# MCXN947_cm33_core0 register map
Vendor: nxp.com; File version: 1.0
CPU: CM33 r2p0, little endian, MPU, FPU, VTOR, 3 interrupt priority bits
Registers are 32-bit, read-write, reset 0x0 unless marked. A register's access mark holds for its fields unless they carry their own. Offsets are from the block's base; [hi:lo] are bit positions; lines under a group give offsets from that group; {n}, {i} and the like mark numbered series; 'fields as' and 'values as' point back to an identical list.

## USBFS0 — USBFS
Base 0x400DD000
0x00 PERID 8-bit ro reset 0x4 — Peripheral ID
  [5:0] ID — Peripheral Identification
0x04 IDCOMP 8-bit ro reset 0xFB — Peripheral ID Complement
  [5:0] NID — Negative Peripheral ID
0x08 REV 8-bit ro reset 0x33 — Peripheral Revision
  [7:0] REV — Revision
0x0C ADDINFO 8-bit ro reset 0x1 — Peripheral Additional Information
  [0] IEHOST — Host Mode Enable
    0=DISABLED; 1=ENABLED
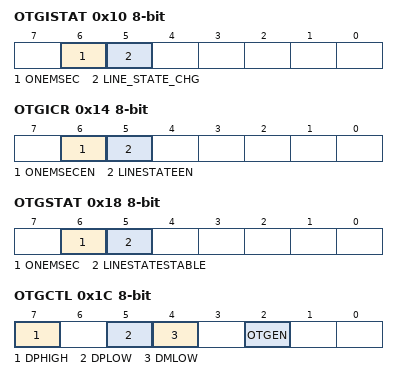
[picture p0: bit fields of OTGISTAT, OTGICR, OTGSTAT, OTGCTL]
0x10 OTGISTAT 8-bit write-1-clears — OTG Interrupt Status
  [6] ONEMSEC write-1-clears — One Millisecond Timer Timeout Flag
    on read: 0=INT_NO (Not timed out); 1=INT_YES (Timed out)
  [5] LINE_STATE_CHG write-1-clears — Line State Change Interrupt Flag
    on read: 0=INT_NO (Interrupt did not occur); 1=INT_YES (Interrupt occurred)
0x14 OTGICR 8-bit — OTG Interrupt Control
  [6] ONEMSECEN — 1-Millisecond Interrupt Enable
    0=DIS_TIMER_INT (Disable); 1=EN_TIMER_INT (Enable)
  [5] LINESTATEEN — Line State Change Interrupt Enable
    0=DIS_LINEST_INT (Disable); 1=EN_LINEST_INT (Enable)
0x18 OTGSTAT 8-bit ro — OTG Status
  [6] ONEMSEC — Reserved for 1 ms count
  [5] LINESTATESTABLE
    0=LINEST_NOT_STABLE (Unstable); 1=LINEST_STABLE (Stable)
0x1C OTGCTL 8-bit — OTG Control
  [7] DPHIGH — D+ Data Line Pullup Resistor Enable
    0=DIS_DP_PULLUP (Disable); 1=EN_DP_PULLUP (Enable)
  [5] DPLOW — D+ Data Line pulldown Resistor Enable
    0=DIS_DP_PULLDOWN (Disable); 1=EN_DP_PULLDOWN (Enable)
  [4] DMLOW — D- Data Line Pulldown Resistor Enable
    0=DIS_DM_PULLDOWN (Disable); 1=EN_DM_PULLDOWN (Enable)
  [2] OTGEN — On-The-Go Pullup and Pulldown Resistor Enable
    0=CONFIG_RESISTORS_CTL (If USBENSOFEN is 1 and HOSTMODEEN is 0 in the Control Register (CTL), then the D+ Data line pullup resistors are enabled. If HOSTMODEEN is 1, then the D+ and D- Data line pulldown resistors are engaged.); 1=CONFIG_RESISTORS_HERE (Uses the pullup and pulldown controls in this register.)
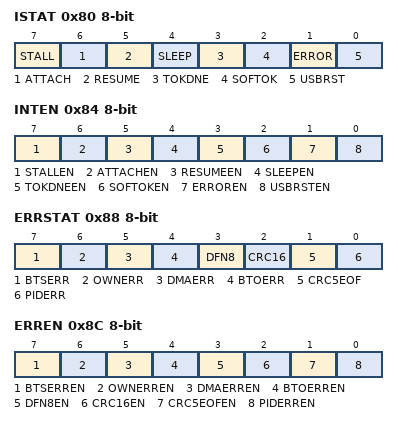
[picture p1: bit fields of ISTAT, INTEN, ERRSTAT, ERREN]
0x80 ISTAT 8-bit write-1-clears — Interrupt Status
  [7] STALL write-1-clears — Stall Interrupt Flag
    values as OTGISTAT.LINE_STATE_CHG
  [6] ATTACH write-1-clears — Attach Interrupt Flag
    on read: 0=INT_NO (Not detected); 1=INT_YES (Detected)
  [5] RESUME write-1-clears — Resume Flag
    values as OTGISTAT.LINE_STATE_CHG
  [4] SLEEP write-1-clears — Sleep Flag
    values as OTGISTAT.LINE_STATE_CHG
  [3] TOKDNE write-1-clears — Current Token Processing Flag
    on read: 0=INT_NO (Not processed); 1=INT_YES (Processed)
  [2] SOFTOK write-1-clears — Start Of Frame (SOF) Token Flag
    on read: 0=INT_NO (Did not receive); 1=INT_YES (Received)
  [1] ERROR write-1-clears — Error Flag
    on read: 0=INT_NO (Error did not occur); 1=INT_YES (Error occurred)
  [0] USBRST write-1-clears — USB Reset Flag
    on read: 0=INT_NO (Not detected); 1=INT_YES (Detected)
0x84 INTEN 8-bit — Interrupt Enable
  [7] STALLEN — STALL Interrupt Enable
    0=DIS_STALL_INT (Disable); 1=EN_STALL_INT (Enable)
  [6] ATTACHEN — ATTACH Interrupt Enable
    0=DIS_ATTACH_INT (Disable); 1=EN_ATTACH_INT (Enable)
  [5] RESUMEEN — RESUME Interrupt Enable
    0=DIS_RESUME_INT (Disable); 1=EN_RESUME_INT (Enable)
  [4] SLEEPEN — SLEEP Interrupt Enable
    0=DIS_SLEEP_INT (Disable); 1=EN_SLEEP_INT (Enable)
  [3] TOKDNEEN — TOKDNE Interrupt Enable
    0=DIS_TOKDNE_INT (Disable); 1=EN_TOKDNE_INT (Enable)
  [2] SOFTOKEN — SOFTOK Interrupt Enable
    0=DIS_SOFTOK_INT (Disable); 1=EN_SOFTOK_INT (Enable)
  [1] ERROREN — ERROR Interrupt Enable
    0=DIS_ERROR_INT (Disable); 1=EN_ERROR_INT (Enable)
  [0] USBRSTEN — USBRST Interrupt Enable
    0=DIS_USBRST_INT (Disable); 1=EN_USBRST_INT (Enable)
0x88 ERRSTAT 8-bit write-1-clears — Error Interrupt Status
  [7] BTSERR write-1-clears — Bit Stuff Error Flag
    on read: 0=INT_NO (Packet not rejected due to the error); 1=INT_YES (Packet rejected due to the error)
  [6] OWNERR write-1-clears — BD Unavailable Error Flag
    values as OTGISTAT.LINE_STATE_CHG
  [5] DMAERR write-1-clears — DMA Access Error Flag
    values as OTGISTAT.LINE_STATE_CHG
  [4] BTOERR write-1-clears — Bus Turnaround Timeout Error Flag
    on read: 0=INT_NO (Not timed out); 1=INT_YES (Timed out)
  [3] DFN8 write-1-clears — Data Field Not 8 Bits Flag
    on read: 0=INT_NO (Integer number of bytes); 1=INT_YES (Not an integer number of bytes)
  [2] CRC16 write-1-clears — CRC16 Error Flag
    on read: 0=INT_NO (Not rejected); 1=INT_YES (Rejected)
  [1] CRC5EOF write-1-clears — CRC5 Error or End of Frame Error Flag
    values as OTGISTAT.LINE_STATE_CHG
  [0] PIDERR write-1-clears — PID Error Flag
    on read: 0=INT_NO (Did not fail); 1=INT_YES (Failed)
0x8C ERREN 8-bit — Error Interrupt Enable
  [7] BTSERREN — BTSERR (Bit Stuff Error) Interrupt Enable
    0=DIS_BTSERREN_INT (Disable); 1=EN_BTSERREN_INT (Enable)
  [6] OWNERREN — OWNERR Interrupt Enable
    0=DIS_OWNERR_INT (Disable); 1=EN_OWNERR_INT (Enable)
  [5] DMAERREN — DMAERR Interrupt Enable
    0=DIS_DMAERR_INT (Disable); 1=EN_DMAERR_INT (Enable)
  [4] BTOERREN — BTOERR (Bus Timeout Error) Interrupt Enable
    0=DIS_BTOERR_INT (Disable); 1=EN_BTOERR_INT (Enable)
  [3] DFN8EN — DFN8 (Data Field Not Integer Number of Bytes) Interrupt Enable
    0=DIS_DFN8_INT (Disable); 1=EN_DFN8_INT (Enable)
  [2] CRC16EN — CRC16 Interrupt Enable
    0=DIS_CRC16_INT (Disable); 1=EN_CRC16_INT (Enable)
  [1] CRC5EOFEN — CRC5/EOF Interrupt Enable
    0=DIS_CRC5_INT (Disable); 1=EN_CRC5_INT (Enable)
  [0] PIDERREN — PIDERR Interrupt Enable
    0=DIS_PIDERR_INT (Disable); 1=EN_PIDERR_INT (Enable)
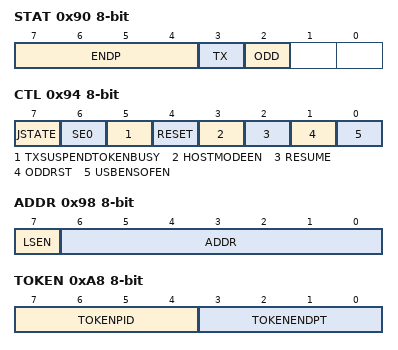
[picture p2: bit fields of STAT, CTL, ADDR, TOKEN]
0x90 STAT 8-bit ro — Status
  [7:4] ENDP — Endpoint address
  [3] TX — Transmit Indicator
    0=RX_TRANSACTION (Receive); 1=TX_TRANSACTION (Transmit)
  [2] ODD — Odd Bank
    0=NOT_IN_ODD_BANK (Not in the odd bank); 1=ODD_BANK (In the odd bank)
0x94 CTL 8-bit — Control
  [7] JSTATE — Live USB Differential Receiver JSTATE Signal
  [6] SE0 — Live USB Single-Ended Zero signal
  [5] TXSUSPENDTOKENBUSY — TXD Suspend And Token Busy
  [4] RESET — Reset Signaling Enable
    0=DISABLE; 1=ENABLE
  [3] HOSTMODEEN — Host Mode Enable
    0=EN_DEVICE_MODE (USBFS operates in Device mode.); 1=EN_HOST_MODE (USBFS operates in Host mode. In Host mode, USBFS performs USB transactions under the programmed control of the host processor.)
  [2] RESUME
  [1] ODDRST — Odd Reset
  [0] USBENSOFEN — USB Enable
    0=DIS_USB_SOF (Disable); 1=EN_USB_SOF (Enable)
0x98 ADDR 8-bit — Address
  [7] LSEN — Low Speed Enable
  [6:0] ADDR — USB Address
0x9C BDTPAGE1 8-bit
  [7:1] BDTBA — BDT Base Address
0xA0 FRMNUML 8-bit ro — Frame Number Register Low
  [7:0] FRM — Frame Number, Bits 0-7
0xA4 FRMNUMH 8-bit ro — Frame Number Register High
  [2:0] FRM — Frame Number, Bits 8-10
0xA8 TOKEN 8-bit
  [7:4] TOKENPID — Token Type
    1=EN_OUT_TOKEN (OUT token. USBFS performs an OUT (TX) transaction.); 9=EN_IN_TOKEN (IN token. USBFS performs an IN (RX) transaction.); 13=EN_SETUP_TOKEN (SETUP token. USBFS performs a SETUP (TX) transaction)
  [3:0] TOKENENDPT — Token Endpoint Address
0xAC SOFTHLD 8-bit — SOF Threshold
  [7:0] CNT — SOF Count Threshold
0xB0 BDTPAGE2 8-bit
  [7:0] BDTBA — BDT Base Address
0xB4 BDTPAGE3 8-bit
  [7:0] BDTBA — BDT Base Address
{0xC0+4i} ENDPOINT[{i}] (i=0..15) group
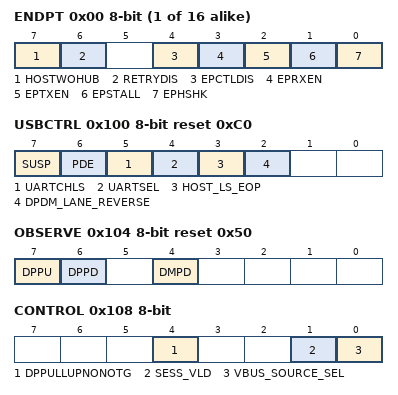
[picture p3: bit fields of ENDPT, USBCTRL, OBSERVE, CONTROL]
  0x00 ENDPT 8-bit — Endpoint Control
    [7] HOSTWOHUB — Host Without A Hub
      0=LS_THRU_HUB (Connected using a hub (USBFS generates PRE_PID as required)); 1=LS_DIRECT_CONNECT (Connected directly to host without a hub, or was used to attach)
    [6] RETRYDIS — Retry Disable
      0=RETRIED (Retried NAK'ed transactions in hardware.); 1=DO_NOT_RETRIED (Do not retry NAK'ed transactions. When a transaction is NAK'ed, the BDT PID field is updated with the NAK PID, and the TOKEN_DNE interrupt becomes 1.)
    [4] EPCTLDIS — Control Transfer Disable
      0=Enable; 1=Disable
    [3] EPRXEN — Endpoint for RX transfers enable
    [2] EPTXEN — Endpoint for TX transfers enable
    [1] EPSTALL — Endpoint Stalled
    [0] EPHSHK — Endpoint Handshaking Enable
0x100 USBCTRL 8-bit reset 0xC0 — USB Control
  [7] SUSP — Suspend
    0=XCVR_NOT_SUSPEND (Not in Suspend state); 1=XCVR_SUSPEND (In Suspend state)
  [6] PDE — Pulldown Enable
    0=DIS_PULLDOWNS (Disable on D+ and D-); 1=EN_PULLDOWNS (Enable on D+ and D-)
  [5] UARTCHLS — UART Signal Channel Select
    0=UART_DP_TX (USB DP and DM signals are used as UART TX/RX.); 1=UART_DM_TX (USB DP and DM signals are used as UART RX/TX.)
  [4] UARTSEL — UART Select
    0=USB_MODE (USB DP and DM external package pins are used for USB signaling.); 1=UART_MODE (USB DP and DM external package pins are used for UART signaling.)
  [3] HOST_LS_EOP — Host-Mode-Only Low-Speed Device EOP Signaling
    0=HOST_FS_RESUME_EOP (Full-speed device or a low-speed device through a hub); 1=HOST_LS_RESUME_EOP (Directly-connected low-speed device)
  [2] DPDM_LANE_REVERSE — DP and DM Lane Reversal Control
    0=DP_DM_STANDARD (Standard USB DP and DM package pin assignment); 1=DP_DM_REVERSED (Reverse roles of USB DP and DM package pins)
0x104 OBSERVE 8-bit ro reset 0x50 — USB OTG Observe
  [7] DPPU — D+ Pullup
    0=DP_PU_DIS_STAT (Disabled); 1=DP_PU_EN_STAT (Enabled)
  [6] DPPD — D+ Pulldown
    0=DP_PD_DIS_STAT (Disabled); 1=DP_PD_EN_STAT (Enabled)
  [4] DMPD — D- Pulldown
    0=DM_PD_DIS_STAT (Disabled); 1=DM_PD_EN_STAT (Enabled)
0x108 CONTROL 8-bit — USB OTG Control
  [4] DPPULLUPNONOTG — DP Pullup in Non-OTG Device Mode
    0=DIS_DEVICE_DP_PU (Disable); 1=EN_DEVICE_DP_PU (Enabled)
  [1] SESS_VLD ro — VBUS Session Valid status
    0=SESS_VLD_LOW (Below); 1=SESS_VLD_HIGH (Above)
  [0] VBUS_SOURCE_SEL — VBUS Monitoring Source Select
    1=RESISTIVE (Resistive divider attached to a GPIO pin)
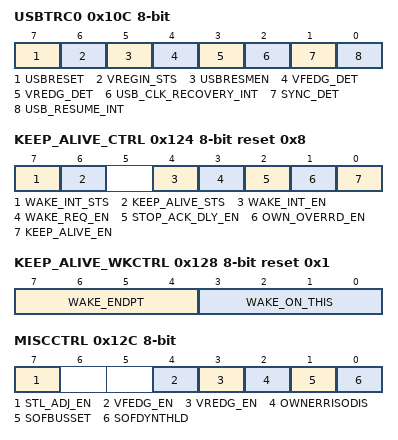
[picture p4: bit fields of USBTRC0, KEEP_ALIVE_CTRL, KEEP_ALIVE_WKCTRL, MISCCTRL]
0x10C USBTRC0 8-bit — USB Transceiver Control 0
  [7] USBRESET wo
    0=NORMAL_OPERATION (Normal USBFS operation); 1=FORCE_HARD_RESET (Returns USBFS to its reset state)
  [6] VREGIN_STS ro — VREGIN Status
  [5] USBRESMEN — Asynchronous Resume Interrupt Enable
    0=DIS_ASYNC_WAKEUP (Disable); 1=EN_ASYNC_WAKEUP (Enable)
  [4] VFEDG_DET ro — VREGIN Falling Edge Interrupt Detect
    0=NO_VREG_FE_INT (Not detected); 1=VREG_FE_INT_DETECTED (Detected)
  [3] VREDG_DET ro — VREGIN Rising Edge Interrupt Detect
    0=NO_VREG_RE_INT (Not detected); 1=VREG_RE_INT_DETECTED (Detected)
  [2] USB_CLK_RECOVERY_INT ro — Combined USB Clock Recovery interrupt status
  [1] SYNC_DET ro — Synchronous USB Interrupt Detect
    0=NO_SYNC_INT (Not detected); 1=SYNC_INT_DETECTED (Detected)
  [0] USB_RESUME_INT ro — USB Asynchronous Interrupt
    0=NO_ASYNC_INT (Not generated); 1=SYNC_INT_GENERATED (Generated because of the USB asynchronous interrupt)
0x114 USBFRMADJUST 8-bit — Frame Adjust
  [7:0] ADJ — Frame Adjustment
0x124 KEEP_ALIVE_CTRL 8-bit reset 0x8 — Keep Alive Mode Control
  [7] WAKE_INT_STS write-1-clears — Wakeup Interrupt Status Flag
    values as OTGISTAT.LINE_STATE_CHG
  [6] KEEP_ALIVE_STS ro — Keep Alive Status
    0=KEEP_ALIVE_DIS_STAT (Not in Keep Alive mode); 1=KEEP_ALIVE_EN_STAT (In Keep Alive mode)
  [4] WAKE_INT_EN — Wakeup Interrupt Enable
  [3] WAKE_REQ_EN — Wakeup Request Enable
    0=DIS_WAKE_REQUEST (Disable); 1=EN_WAKE_REQUEST (Enable)
  [2] STOP_ACK_DLY_EN — Stop Acknowledge Delay Enable
    0=ENTER_KEEP_ALIVE_ON_IDLE (Enter KEEP_ALIVE mode immediately when there is no USB AHB transfer.); 1=ENTER_KEEP_ALIVE_IMMEDIATE (Enter KEEP_ALIVE mode until the USB core is idle and there is no USB AHB transfer.)
  [1] OWN_OVERRD_EN — OWN Bit Override Enable
  [0] KEEP_ALIVE_EN — Keep Alive Mode Enable
    0=DE_ASSERTED (Everything remains same as before.); 1=ASSERTED (USB shall enter USB_KEEP_ALIVE mode after asserting ipg_stop.)
0x128 KEEP_ALIVE_WKCTRL 8-bit reset 0x1 — Keep Alive Mode Wakeup Control
  [7:4] WAKE_ENDPT ro — Endpoint address for the wakeup request
  [3:0] WAKE_ON_THIS — Token PID for the wakeup request
    1=WAKE_ON_OUT_SETUP (Wake up after receiving OUT or SETUP token packet.); 13=WAKE_ON_SETUP_ONLY (Wake up after receiving SETUP token packet. All other values are reserved.)
0x12C MISCCTRL 8-bit — Miscellaneous Control
  [7] STL_ADJ_EN — USB Peripheral Mode Stall Adjust Enable
    0=STALL_BOTH_IN_OUT (If ENDPTn[END_STALL] = 1, both IN and OUT directions for the associated endpoint stalls.); 1=STALL_SINGLE_DIRECTION (If ENDPTn[END_STALL] = 1, the STALL_xx_DIS registers control which directions for the associated endpoint stalls.)
  [4] VFEDG_EN — VREGIN Falling Edge Interrupt Enable
    0=DIS_VREGIN_FE_INT (Disable); 1=EN_VREGIN_FE_INT (Enable)
  [3] VREDG_EN — VREGIN Rising Edge Interrupt Enable
    0=DIS_VREGIN_RE_INT (Disable); 1=EN_VREGIN_RE_INT (Enable)
  [2] OWNERRISODIS — OWN Error Detect for ISO IN and ISO OUT Disable
    0=DIS_OWN_ERROR_DETECT_ISO (Enable); 1=EN_OWN_ERROR_DETECT_ISO (Disable)
  [1] SOFBUSSET — SOF_TOK Interrupt Generation Mode Select
    0=SOF_TOK_INT_FROM_THRESHOLD (According to the SOF threshold value); 1=SOF_TOK_INT_COUNTER_0 (When the SOF counter reaches 0)
  [0] SOFDYNTHLD — Dynamic SOF Threshold Compare mode
    0=USE_DYN_SOF_THRESHOLD (When the byte-times SOF threshold is reached); 1=USE_FIXED_SOF_THRESHOLD (When 8 byte-times SOF threshold is reached or overstepped)
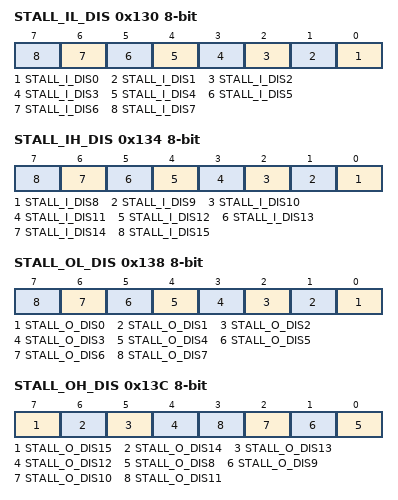
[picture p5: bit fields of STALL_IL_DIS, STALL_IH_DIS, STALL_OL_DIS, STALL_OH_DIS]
0x130 STALL_IL_DIS 8-bit — Peripheral Mode Stall Disable for Endpoints 7 to 0 in IN Direction
  [n] STALL_I_DIS{n} (n=0..7) — Disable Endpoint {n} IN Direction
    0=EN_EP{n}_IN_STALL (Enable); 1=DIS_EP{n}_IN_STALL (Disable)
0x134 STALL_IH_DIS 8-bit — Peripheral Mode Stall Disable for Endpoints 15 to 8 in IN Direction
  [n-8] STALL_I_DIS{n} (n=8..15) — Disable Endpoint {n} IN Direction
    0=EN_EP{n}_IN_STALL (Enable); 1=DIS_EP{n}_IN_STALL (Disable)
0x138 STALL_OL_DIS 8-bit — Peripheral Mode Stall Disable for Endpoints 7 to 0 in OUT Direction
  [n] STALL_O_DIS{n} (n=0..7) — Disable Endpoint {n} OUT Direction
    0=EN_EP{n}_OUT_STALL (Enable); 1=DIS_EP{n}_OUT_STALL (Disable)
0x13C STALL_OH_DIS 8-bit — Peripheral Mode Stall Disable for Endpoints 15 to 8 in OUT Direction
  [7] STALL_O_DIS15 — Disable Endpoint 15 OUT Direction
    0=EN_EP15_OUT_STALL (Enable); 1=DIS_EP15_OUT_STALL (Disable)
  [6] STALL_O_DIS14 — Disable Endpoint 14 OUT Direction
    0=EN_EP14_OUT_STALL (Enable); 1=DIS_EP14_OUT_STALL (Disable)
  [5] STALL_O_DIS13 — Disable Endpoint 13 OUT Direction
    0=EN_EP13_OUT_STALL (Enable); 1=DIS_EP13_OUT_STALL (Disable)
  [4] STALL_O_DIS12 — Disable endpoint 12 OUT direction
    0=EN_EP12_OUT_STALL (Enable); 1=DIS_EP12_OUT_STALL (Disable)
  [n-8] STALL_O_DIS{n} (n=8..11) — Disable Endpoint {n} OUT Direction
    values as STALL_OL_DIS.STALL_O_DIS0
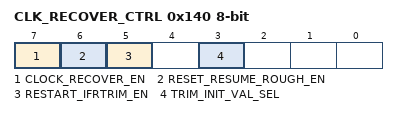
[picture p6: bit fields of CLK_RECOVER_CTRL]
0x140 CLK_RECOVER_CTRL 8-bit — USB Clock Recovery Control
  [7] CLOCK_RECOVER_EN — Crystal-Less USB Enable
    0=DIS_CLK_RECOVER (Disable); 1=EN_CLK_RECOVER (Enable)
  [6] RESET_RESUME_ROUGH_EN — Reset or Resume to Rough Phase Enable
    0=KEEP_TRIM_FINE_ON_RESET (Always works in tracking phase after the first time rough phase, to track transition.); 1=USE_IFR_TRIM_FINE_ON_RESET (Go back to rough stage whenever a bus reset or bus resume occurs.)
  [5] RESTART_IFRTRIM_EN — Restart from IFR Trim Value
    0=LOAD_TRIM_FINE_MID (Trim fine adjustment always works based on the previous updated trim fine value.); 1=LOAD_TRIM_FINE_IFR (Trim fine restarts from the IFR trim value whenever you detect bus_reset or bus_resume or deassert module enable.)
  [3] TRIM_INIT_VAL_SEL — Selects the source for the initial FIRC trim fine value used after a reset.
    0=INIT_TRIM_FINE_MID (Mid-scale); 1=INIT_TRIM_FINE_IFR (IFR)
0x144 CLK_RECOVER_IRC_EN 8-bit reset 0x1 — FIRC Oscillator Enable
  [1] IRC_EN — Fast IRC enable
    0=DIS_IRC (Disable); 1=EN_IRC (Enable)
0x154 CLK_RECOVER_INT_EN 8-bit reset 0x10 — Clock Recovery Combined Interrupt Enable
  [4] OVF_ERROR_EN — Overflow error interrupt enable
    0=MASK_OVF_ERR_INT (The interrupt is masked); 1=EN_OVF_ERR_INT (The interrupt is enabled)
0x15C CLK_RECOVER_INT_STATUS 8-bit write-1-clears — Clock Recovery Separated Interrupt Status
  [4] OVF_ERROR write-1-clears — Overflow Error Interrupt Status Flag
    on read: 0=INT_NO (Interrupt did not occur); 1=INT_YES (Unmasked interrupt occurred)
